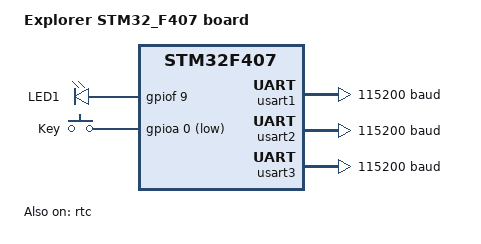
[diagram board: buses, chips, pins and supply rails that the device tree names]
/*
 * Copyright (c) 2017, Erwin Rol <erwin@erwinrol.com>
 *
 * SPDX-License-Identifier: Apache-2.0
 */

/dts-v1/;
#include <st/f4/stm32f407Xg.dtsi>

/ {
	model = "Explorer STM32_F407 board";
	compatible = "explorer,stm32_f407", "st,stm32f407";

	chosen {
		zephyr,console = &usart1;
		zephyr,shell-uart = &usart1;
		zephyr,sram = &sram0;
		zephyr,flash = &flash0;
		zephyr,ccm = &ccm0;
	};

	leds {
		compatible = "gpio-leds";
		green_led_1: led_1 {
			gpios = <&gpiof 9 GPIO_INT_ACTIVE_HIGH>;
			label = "LED1";
		};
	};

	gpio_keys {
		compatible = "gpio-keys";
		user_button: button {
			label = "Key";
			gpios = <&gpioa 0 GPIO_INT_ACTIVE_LOW>;
		};
	};

	aliases {
		led0 = &green_led_1;
		sw0 = &user_button;
	};
};

&usart1 {
	current-speed = <115200>;
	pinctrl-0 = <&usart1_pins_a>;
	pinctrl-names = "default";
	status = "ok";
};

&usart2 {
	current-speed = <115200>;
	pinctrl-0 = <&usart2_pins_a>;
	pinctrl-names = "default";
	status = "ok";
};

&usart3 {
	current-speed = <115200>;
	pinctrl-0 = <&usart3_pins_b>;
	pinctrl-names = "default";
	status = "ok";
};

&rtc {
	status = "ok";
};
